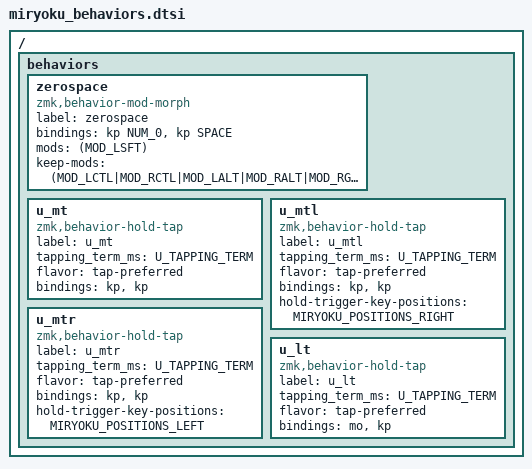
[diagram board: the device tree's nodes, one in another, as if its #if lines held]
// Copyright 2022 Manna Harbour
// https://github.com/manna-harbour/miryoku

/ {
  behaviors {
    zerospace: zerospace {
      compatible = "zmk,behavior-mod-morph";
      label = "zerospace";
      #binding-cells = <0>;
      bindings = <&kp NUM_0>, <&kp SPACE>;
      mods = <(MOD_LSFT)>;
      keep-mods = <(MOD_LCTL|MOD_RCTL|MOD_LALT|MOD_RALT|MOD_RGUI|MOD_LGUI)>;
    };
    u_mt: u_mt {
      compatible = "zmk,behavior-hold-tap";
      label = "u_mt";
      #binding-cells = <2>;
      tapping_term_ms = <U_TAPPING_TERM>;
      flavor = "tap-preferred";
      bindings = <&kp>, <&kp>;
    };
    u_mtl: u_mtl {
      compatible = "zmk,behavior-hold-tap";
      label = "u_mtl";
      #binding-cells = <2>;
      tapping_term_ms = <U_TAPPING_TERM>;
      flavor = "tap-preferred";
      bindings = <&kp>, <&kp>;
#ifdef MIRYOKU_POSITIONAL_MODS
#ifdef MIRYOKU_POSITIONS_RIGHT
      hold-trigger-key-positions = <MIRYOKU_POSITIONS_RIGHT>;
#endif
#endif
    };
    u_mtr: u_mtr {
      compatible = "zmk,behavior-hold-tap";
      label = "u_mtr";
      #binding-cells = <2>;
      tapping_term_ms = <U_TAPPING_TERM>;
      flavor = "tap-preferred";
      bindings = <&kp>, <&kp>;
#ifdef MIRYOKU_POSITIONAL_MODS
#ifdef MIRYOKU_POSITIONS_LEFT
      hold-trigger-key-positions = <MIRYOKU_POSITIONS_LEFT>;
#endif
#endif
    };
    u_lt: u_lt {
      compatible = "zmk,behavior-hold-tap";
      label = "u_lt";
      #binding-cells = <2>;
      tapping_term_ms = <U_TAPPING_TERM>;
      flavor = "tap-preferred";
      bindings = <&mo>, <&kp>;
    };
  };
};
